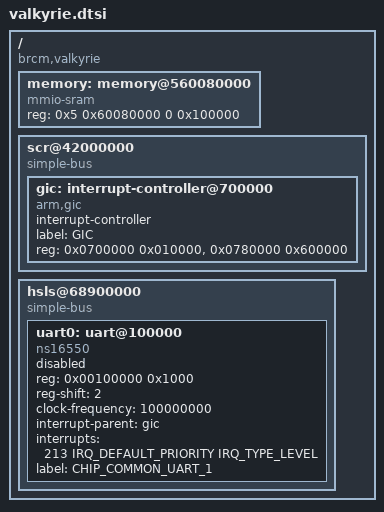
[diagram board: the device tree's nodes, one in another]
/*
 * Copyright (C) 2019 Broadcom. All Rights Reserved.
 * The term "Broadcom" refers to Broadcom Inc. and/or its subsidiaries.
 *
 * SPDX-License-Identifier: Apache-2.0
 */

#include <dt-bindings/interrupt-controller/arm-gic.h>

/ {
	compatible = "brcm,valkyrie";
	#address-cells = <2>;
	#size-cells = <2>;

	memory: memory@560080000 {
		device_type = "memory";
		/*
		 * FIXME: Not to be confused with compatible string "mmio-sram",
		 * this is actually DDR region.
		 * This region specifies Zephyr execution region.
		 */
		compatible = "mmio-sram";
		reg = <0x5 0x60080000 0 0x100000>;
	};

	scr@42000000 {
		compatible = "simple-bus";#address-cells = <1>;
		#size-cells = <1>;
		ranges = <0x0 0x0 0x42000000 0x05000000>;

		gic: interrupt-controller@700000 {
			compatible = "arm,gic";
			#interrupt-cells = <3>;
			#address-cells = <1>;
			#size-cells = <1>;
			ranges;
			interrupt-controller;
			label = "GIC";
			reg = <0x0700000 0x010000>, /* GICD */
			<0x0780000 0x600000>; /* GICR */
		};
	};

	hsls@68900000 {
		compatible = "simple-bus";
		#address-cells = <1>;
		#size-cells = <1>;
		ranges = <0x0 0x0 0x48000000 0x10000000>;

		uart0: uart@100000 {
			device_type = "serial";
			compatible = "ns16550";
			reg = <0x00100000 0x1000>;
			reg-shift = <2>;
			clock-frequency = <100000000>;
			interrupt-parent = <&gic>;
			interrupts = <213 IRQ_DEFAULT_PRIORITY IRQ_TYPE_LEVEL>;
			label = "CHIP_COMMON_UART_1";
			status = "disabled";
		};
	};
};
